# tviic2d6mddr register map
Vendor: Cypress Semiconductor; Series: tviic2d6mddr; File version: 1.0
CPU: CM7 r0p1, little endian, MPU, FPU, VTOR, 3 interrupt priority bits
Registers are 32-bit, read-write, reset 0x0 unless marked. A register's access mark holds for its fields unless they carry their own. Offsets are from the block's base; [hi:lo] are bit positions; lines under a group give offsets from that group; 'fields as' and 'values as' point back to an identical list.

## VIDEOSS0 (part 18 of 18) — Video and Graphics Subsystem IP
Base 0x40A00000
0xC8000 FPDLINK1 group — FPD-Link Interface
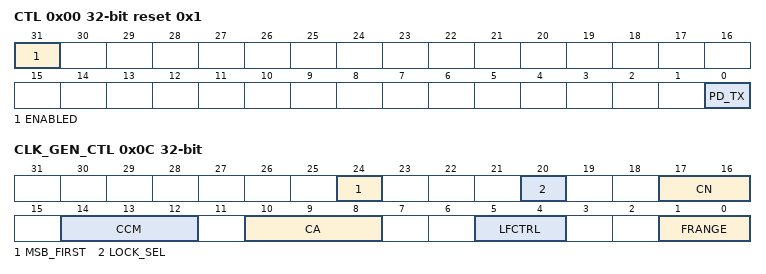
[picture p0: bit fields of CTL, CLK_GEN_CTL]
  0x00 CTL reset 0x1 — IP Control register for FPDLink
    [31] ENABLED — Enable bit for FPDLink
      0=DIS (Disable the entire mxvideoss_fpdlink); 1=EN (Enable FPDLink)
    [0] PD_TX — Power down bit, when high all blocks inside the FPDLink block shall be powered down
      1=FPDLINK_POWER_DOWN (Power down FPDLink, this is the default reset value); 0=FPDLINK_POWER_UP (Power up FPDLink)
  0x04 CMD — IP Command register for FPDLink
    [0] LVDS_TX_EN — Enable the serializers and TX drivers for all lanes of FPDLink
      0=FPDLINK_TX_DRIVER_DISABLED (Disable FPDLink TX operation); 1=FPDLINK_TX_DRIVER_ENABLED (Enable FPDLink TX operation)
  0x08 CLK_GEN_CMD — Control register for CLK_GEN
    [0] MODE8 — Enable Dual-Pixel (8-Lane Mode)
      0=MODE4 (4 Lane LVDS mode); 1=MODE8 (8 lane LVDS mode)
  0x0C CLK_GEN_CTL — Configuration register for CKGEN
    [24] MSB_FIRST — Controls parallel to serial transmission order of input 7-bit word
      0=LSB (LSB bit is sent first); 1=MSB (MSB bit is sent first. This is the default value)
    [20] LOCK_SEL — Select internal or external PLL lock
      0=INT (Select Internal Lock. This is the default value); 1=EXT (Select External Lock)
    [17:16] CN — Control N divider used for low bandwidth feature
      0=DIV1 (Default bandwidth as per specification); 1=DIV2 (Intermediate bandwidth setting lower than default bandwidth (higher than 0x2 setting)); 2=DIV4 (Intermediate bandwidth setting higher than 800kHz (lower than 0x01 setting)); 3=DIV8 (Less than 800kHz)
    [14:12] CCM — Common mode voltage control bits.
      0=1P05 (Common mode voltage set to 1.05); 1=1P10 (Common mode voltage set to 1.10); 2=1P15 (Common mode voltage set to 1.15); 3=1P20 (Common mode voltage set to 1.20); 4=1P25 (Common mode voltage set to 1.25, this is the default value to be programmed); 5=1P30 (Common mode voltage set to 1.30); 6=1P35 (Common mode voltage set to 1.35); 7=1P40 (Common mode voltage set to 1.40)
    [10:8] CA — Driver output current control bits
      0=2P4MA (Driver output current is 2.4mA); 1=2P72MA (Driver output current is 2.72mA); 2=2P88MA (Driver output current is 2.88mA); 3=3P2MA (Driver output current is 3.2mA); 4=3P36MA (Driver output current is 3.36ma, this is the default value to be programmed); 5=3P68MA (Driver output current is 3.68mA); 6=3P84MA (Driver output current is 3.84mA); 7=4P32MA (Driver output current is 4.32mA)
    [5:4] LFCTRL — Loop filter resistance selection used for low bandwidth feature
      values as CN
    [1:0] FRANGE — Control Output frequency divider, connects to the port CO on the hardIP
      0=DIV1 (Internal PLL output divider programmed to 1); 1=DIV2 (Internal PLL output divider programmed to 2); 2=DIV4 (Internal PLL output divider programmed to 4); 3=DIV8 (Internal PLL output divider programmed to 8)
  0x10 CLK_GEN_STATUS ro — Status register for CKGEN
    [0] PLL_LOCK — Lock Detect output. Asserted when the PLL has achieved frequency lock

## PD — Power Domain and Switch Block
Base 0x40B00000
0x00 CTL — Power Domain Control
  [1:0] PWR_MODE — Power mode. PWR_DONE flag indicates that the programmed PWR_MODE has been reached. Do not change PWR_MODE if PWR_DONE==0.
    0=OFF (Power domain is switched off.); 1=RESET (Power domain is in reset.); 2=RETAINED (Power domain is switched off, but specified state is retained. This choice behaves like OFF for domains that do not support retained state at all (RETENTION_PRESENT=0).); 3=ENABLED (Power domain is switched on.)
0x10 STATUS ro reset 0x10 — Power Domain Status
  [4] PWR_DONE — This flag indicates if the power mode has taken effect or not.
0x80 TRIM — Power Switch Trim
  [1:0] PWRSW_WAIT_CNT — Divider control, specified as the number of wait cycles inserted between output clock pulses. Do not change this value while any switch is transitioning.
